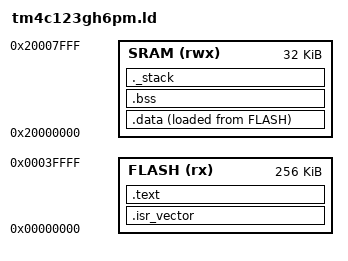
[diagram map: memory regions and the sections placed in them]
/**
 * Linker script for TM4C123GH6PM
 * 256KB Flash, 32KB SRAM
 */

MEMORY
{
    FLASH (rx)  : ORIGIN = 0x00000000, LENGTH = 256K
    SRAM  (rwx) : ORIGIN = 0x20000000, LENGTH = 32K
}

/* Stack at top of SRAM */
_estack = ORIGIN(SRAM) + LENGTH(SRAM);

SECTIONS
{
    /* Interrupt vector table at start of Flash */
    .isr_vector :
    {
        . = ALIGN(4);
        KEEP(*(.isr_vector))
        . = ALIGN(4);
    } > FLASH

    /* Code and read-only data */
    .text :
    {
        . = ALIGN(4);
        *(.text)
        *(.text*)
        *(.rodata)
        *(.rodata*)
        . = ALIGN(4);
        _etext = .;
    } > FLASH

    /* Initialized data - stored in Flash, copied to SRAM at startup */
    _sidata = LOADADDR(.data);
    
    .data :
    {
        . = ALIGN(4);
        _sdata = .;
        *(.data)
        *(.data*)
        . = ALIGN(4);
        _edata = .;
    } > SRAM AT> FLASH

    /* Uninitialized data - zeroed at startup */
    .bss :
    {
        . = ALIGN(4);
        _sbss = .;
        *(.bss)
        *(.bss*)
        *(COMMON)
        . = ALIGN(4);
        _ebss = .;
    } > SRAM

    /* Ensure minimum stack size */
    ._stack :
    {
        . = ALIGN(8);
        . = . + 0x400; /* 1KB minimum stack */
        . = ALIGN(8);
    } > SRAM
}

